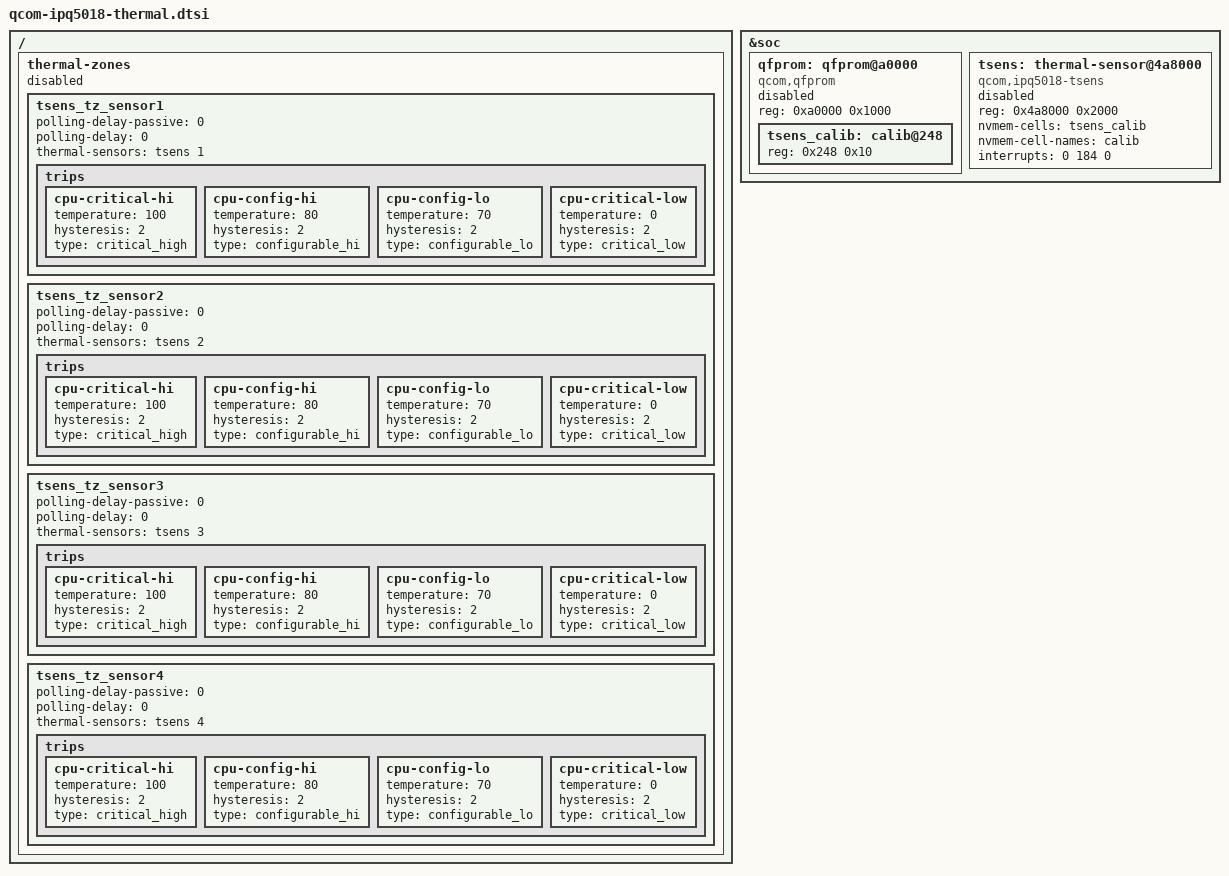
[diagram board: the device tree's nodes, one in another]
/*
 * Copyright (c) 2017, 2020 The Linux Foundation. All rights reserved.
 *
 * Permission to use, copy, modify, and/or distribute this software for any
 * purpose with or without fee is hereby granted, provided that the above
 * copyright notice and this permission notice appear in all copies.
 *
 * THE SOFTWARE IS PROVIDED "AS IS" AND THE AUTHOR DISCLAIMS ALL WARRANTIES
 * WITH REGARD TO THIS SOFTWARE INCLUDING ALL IMPLIED WARRANTIES OF
 * MERCHANTABILITY AND FITNESS. IN NO EVENT SHALL THE AUTHOR BE LIABLE FOR
 * ANY SPECIAL, DIRECT, INDIRECT, OR CONSEQUENTIAL DAMAGES OR ANY DAMAGES
 * WHATSOEVER RESULTING FROM LOSS OF USE, DATA OR PROFITS, WHETHER IN AN
 * ACTION OF CONTRACT, NEGLIGENCE OR OTHER TORTIOUS ACTION, ARISING OUT OF
 * OR IN CONNECTION WITH THE USE OR PERFORMANCE OF THIS SOFTWARE.
 */

/ {
	thermal-zones {
		status = "disabled";
		tsens_tz_sensor1 {
			polling-delay-passive = <0>;
			polling-delay = <0>;
			thermal-sensors = <&tsens 1>;

			trips {
				cpu-critical-hi {
					temperature = <100>;
					hysteresis = <2>;
					type = "critical_high";
				};

				cpu-config-hi {
					temperature = <80>;
					hysteresis = <2>;
					type = "configurable_hi";
				};

				cpu-config-lo {
					temperature = <70>;
					hysteresis = <2>;
					type = "configurable_lo";
				};

				cpu-critical-low {
					temperature = <0>;
					hysteresis = <2>;
					type = "critical_low";
				};
			};
		};

		tsens_tz_sensor2 {
			polling-delay-passive = <0>;
			polling-delay = <0>;
			thermal-sensors = <&tsens 2>;

			trips {
				cpu-critical-hi {
					temperature = <100>;
					hysteresis = <2>;
					type = "critical_high";
				};

				cpu-config-hi {
					temperature = <80>;
					hysteresis = <2>;
					type = "configurable_hi";
				};

				cpu-config-lo {
					temperature = <70>;
					hysteresis = <2>;
					type = "configurable_lo";
				};

				cpu-critical-low {
					temperature = <0>;
					hysteresis = <2>;
					type = "critical_low";
				};
			};
		};

		tsens_tz_sensor3 {
			polling-delay-passive = <0>;
			polling-delay = <0>;
			thermal-sensors = <&tsens 3>;

			trips {
				cpu-critical-hi {
					temperature = <100>;
					hysteresis = <2>;
					type = "critical_high";
				};

				cpu-config-hi {
					temperature = <80>;
					hysteresis = <2>;
					type = "configurable_hi";
				};

				cpu-config-lo {
					temperature = <70>;
					hysteresis = <2>;
					type = "configurable_lo";
				};

				cpu-critical-low {
					temperature = <0>;
					hysteresis = <2>;
					type = "critical_low";
				};
			};
		};

		tsens_tz_sensor4 {
			polling-delay-passive = <0>;
			polling-delay = <0>;
			thermal-sensors = <&tsens 4>;

			trips {
				cpu-critical-hi {
					temperature = <100>;
					hysteresis = <2>;
					type = "critical_high";
				};

				cpu-config-hi {
					temperature = <80>;
					hysteresis = <2>;
					type = "configurable_hi";
				};

				cpu-config-lo {
					temperature = <70>;
					hysteresis = <2>;
					type = "configurable_lo";
				};

				cpu-critical-low {
					temperature = <0>;
					hysteresis = <2>;
					type = "critical_low";
				};
			};
		};
	};
};

&soc {
	qfprom: qfprom@a0000 {
		#address-cells = <1>;
		#size-cells = <1>;
		compatible = "qcom,qfprom";
		reg = <0xa0000 0x1000>;
		status = "disabled";
		tsens_calib: calib@248 {
			reg = <0x248 0x10>;
		};
	};

	tsens: thermal-sensor@4a8000 {
		compatible = "qcom,ipq5018-tsens";
		reg = <0x4a8000 0x2000>;
		nvmem-cells = <&tsens_calib>;
		nvmem-cell-names = "calib";
		interrupts = <0 184 0>;
		#thermal-sensor-cells = <1>;
		status = "disabled";
	};
};
